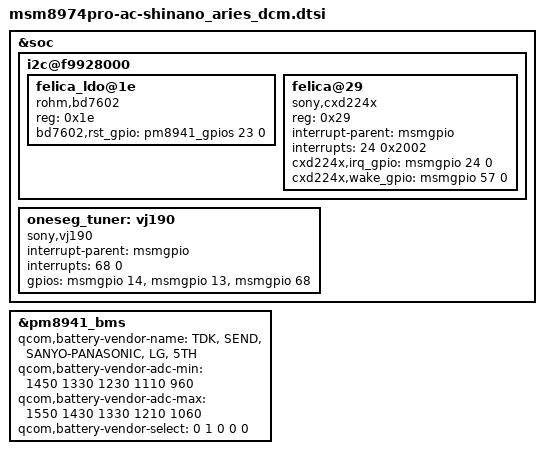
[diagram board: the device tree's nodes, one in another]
/* arch/arm/boot/dts/msm8974pro-ac-shinano_aries_dcm.dtsi
 *
 * Copyright (C) 2014 Sony Mobile Communications AB.
 *
 * Author: Kouhei Fujiya <Kouhei.X.Fujiya@sonymobile.com>
 *
 * This program is free software; you can redistribute it and/or modify
 * it under the terms of the GNU General Public License version 2 and
 * only version 2 as published by the Free Software Foundation.
 *
 * This program is distributed in the hope that it will be useful,
 * but WITHOUT ANY WARRANTY; without even the implied warranty of
 * MERCHANTABILITY or FITNESS FOR A PARTICULAR PURPOSE.  See the
 * GNU General Public License for more details.
 */

&soc {
	/* I2C : BLSP6 */
	i2c@f9928000 {
		felica_ldo@1e {
			compatible = "rohm,bd7602";
			reg = <0x1e>;
			bd7602,rst_gpio = <&pm8941_gpios 23 0>;
		};
		felica@29 {
			compatible = "sony,cxd224x";
			reg = <0x29>;
			interrupt-parent = <&msmgpio>;
			interrupts = <24 0x2002>;
			cxd224x,irq_gpio = <&msmgpio 24 0>;
			cxd224x,wake_gpio = <&msmgpio 57 0>;
		};
	};

	oneseg_tuner: vj190 {
		compatible = "sony,vj190";
		interrupt-parent = <&msmgpio>;
		interrupts = <68 0>;
		gpios =
			<&msmgpio 14 0>, /* TUNER_POWER */
			<&msmgpio 13 0>, /* TUNER_RESET */
			<&msmgpio 68 0>; /* TUNER_INT */
	};
};

&pm8941_bms {
	qcom,battery-vendor-name = "TDK", "SEND", "SANYO-PANASONIC", "LG", "5TH";
	qcom,battery-vendor-adc-min = <1450 1330 1230 1110 960>;
	qcom,battery-vendor-adc-max = <1550 1430 1330 1210 1060>;
	qcom,battery-vendor-select = <0 1 0 0 0>;
};
